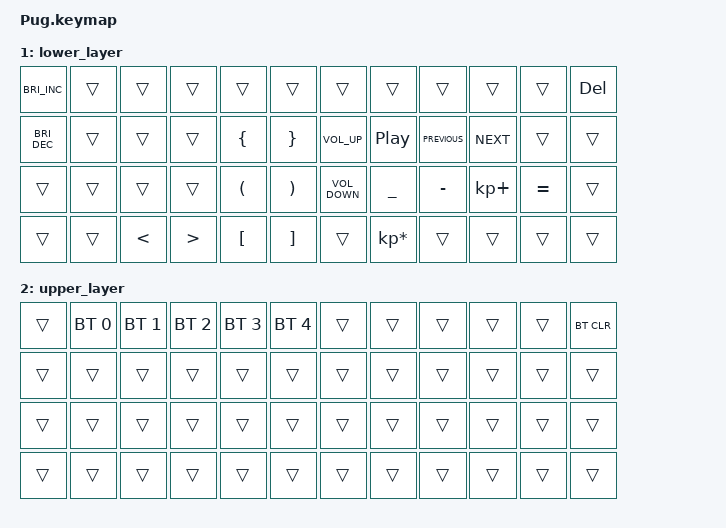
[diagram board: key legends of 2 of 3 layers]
#include <behaviors.dtsi>
#include <dt-bindings/zmk/bt.h>
#include <dt-bindings/zmk/keys.h>

/ {
    behaviors {
        HMR: HMR {
            compatible = "zmk,behavior-hold-tap";
            label = "HMR";
            bindings = <&kp>, <&kp>;

            #binding-cells = <2>;
            tapping-term-ms = <280>;
            quick-tap-ms = <175>;
            flavor = "tap-preferred";
            hold-trigger-key-positions = <6 7 8 9 10 11 18 19 20 21 22 23 30 31 32 33 34 35 42 43 44 45 46 47 54 55 56 57 58 59 66 67 68 69 70 71>;
            hold-trigger-on-release;
        };

        HML: HML {
            compatible = "zmk,behavior-hold-tap";
            label = "HML";
            bindings = <&kp>, <&kp>;

            #binding-cells = <2>;
            tapping-term-ms = <280>;
            quick-tap-ms = <175>;
            flavor = "tap-preferred";
            hold-trigger-on-release;
            hold-trigger-key-positions = <0 1 2 3 4 5 12 13 14 15 16 17 24 25 26 27 28 29 36 37 38 39 40 41 48 49 50 51 52 53 60 61 62 63 64 65>;
        };
    };

    keymap {
        compatible = "zmk,keymap";

        default_layer {
            // This is just a keyboard layout top layer
            // ---------------------------------------------------------------------------------
            // |   `  |  1  |  2  |  3  |  4  |  5  |     |  6  |  7  |  8  |  9  |  0  | BKSP |
            // |  TAB |  Q  |  W  |  E  |  R  |  T  |     |  Y  |  U  |  I  |  O  |  P  |  \   |
            // | CAPS |  A  |  S  |  D  |  F  |  G  |     |  H  |  J  |  K  |  L  |  ;  |  ENT |
            // | SHFT |  Z  |  X  |  C  |  V  |  B  |     |  N  |  M  |  ,  |  .  |  /  | APOS |
            // | CTRL | ALT | GUI | SPC | SPC | SPC |     | SPC | LOW |LARW |DARW |UARW | RARW |

            bindings = <
&HML ESC GRAVE    &kp N1        &kp N2        &kp N3  &kp N4        &kp N5       &kp N6     &kp N7  &kp N8     &kp N9          &kp N0    &kp BACKSPACE
&kp TAB           &kp Q         &kp W         &kp E   &kp R         &kp T        &kp Y      &kp U   &kp I      &kp O           &kp P     &kp BSLH
&kp CAPS          &kp A         &HML LC(S) S  &kp D   &HML LC(F) F  &kp G        &kp H      &kp J   &kp K      &kp L           &kp SEMI  &kp RETURN
&kp LSHFT         &kp Z         &kp X         &kp C   &kp V         &kp B        &kp N      &kp M   &kp COMMA  &kp DOT         &kp FSLH  &kp APOS
&kp LEFT_CONTROL  &kp LEFT_ALT  &trans        &mo 2   &kp LEFT_GUI  &kp SPACE    &kp SPACE  &mo 1   &kp LEFT   &kp DOWN_ARROW  &kp UP    &kp RIGHT
            >;
        };

        lower_layer {
            // This is just a keyboard layout layer 2
            // ------------------------------------------------------------------------------------------------------------
            // |       |  BT1  |  BT2  |  BT3  |  BT4  |  BT5  |          |       |       |       |       |       | BTCLR |
            // |       |       |       |       |       |       |          |       |       |       |       |       |       |
            // |       |       |       | LPAR  | RPAR  |       |          |       | LBKT  | RBKT  |       |       |       |
            // |       |       |       |       |       |       |          |       |       |       |       |       |       |

            bindings = <
&kp C_BRIGHTNESS_INC  &trans  &trans         &trans            &trans                &trans                   &trans             &trans            &trans          &trans       &trans     &kp DEL
&kp C_BRIGHTNESS_DEC  &trans  &trans         &trans            &kp LEFT_BRACE        &kp RIGHT_BRACE          &kp C_VOLUME_UP    &kp C_PLAY_PAUSE  &kp C_PREVIOUS  &kp C_NEXT   &trans     &trans
&trans                &trans  &trans         &trans            &kp LEFT_PARENTHESIS  &kp RIGHT_PARENTHESIS    &kp C_VOLUME_DOWN  &kp UNDERSCORE    &kp MINUS       &kp KP_PLUS  &kp EQUAL  &trans
&trans                &trans  &kp LESS_THAN  &kp GREATER_THAN  &kp LEFT_BRACKET      &kp RIGHT_BRACKET        &trans             &kp KP_MULTIPLY   &trans          &trans       &trans     &trans
            >;
        };

        upper_layer {
            bindings = <
&trans  &bt BT_SEL 0  &bt BT_SEL 1  &bt BT_SEL 2  &bt BT_SEL 3  &bt BT_SEL 4    &trans  &trans  &trans  &trans  &trans  &bt BT_CLR
&trans  &trans        &trans        &trans        &trans        &trans          &trans  &trans  &trans  &trans  &trans  &trans
&trans  &trans        &trans        &trans        &trans        &trans          &trans  &trans  &trans  &trans  &trans  &trans
&trans  &trans        &trans        &trans        &trans        &trans          &trans  &trans  &trans  &trans  &trans  &trans
            >;
        };
    };
};
